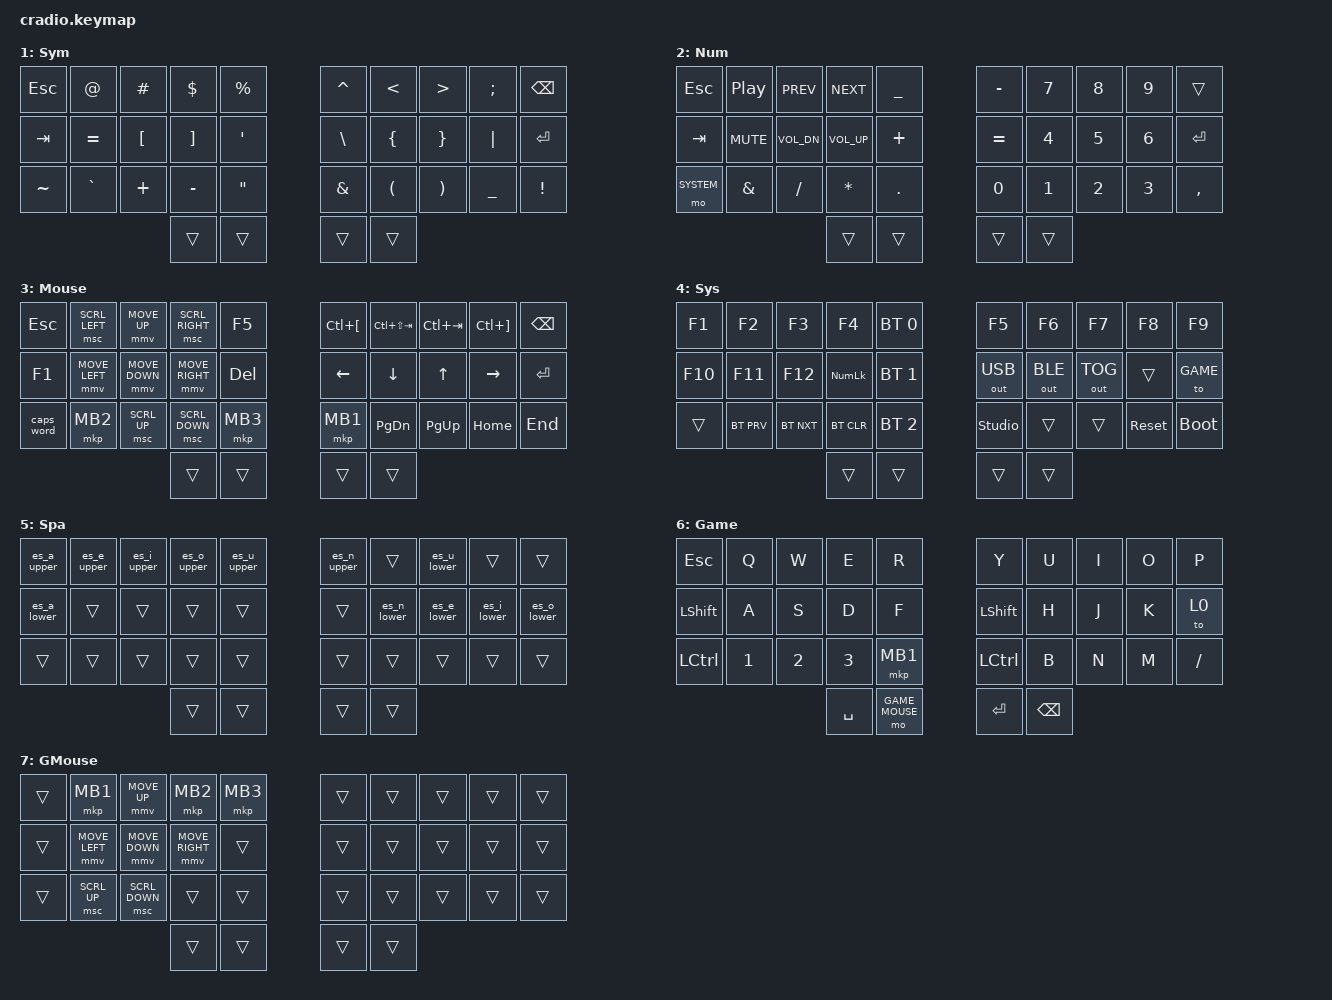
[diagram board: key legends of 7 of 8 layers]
// Copyright (c) 2022 The ZMK Contributors
// SPDX-License-Identifier: MIT

#include <behaviors.dtsi>
#include <dt-bindings/zmk/keys.h>
#include <dt-bindings/zmk/bt.h>
#include <dt-bindings/zmk/pointing.h>
#include <dt-bindings/zmk/outputs.h>
#include "spanish.dtsi"

// Layers adapted from benvallack/zmk-config at 84ae125986b18e1e6dfb1f2a6a15777429f29520.
// Keep numeric indices 1/2: the unchanged base thumb bindings refer to them.
#define SYMBOLS 1
#define NUMBERS 2
#define NAV 3
#define SYSTEM 4
#define SPANISH 5
#define GAME 6
#define GAME_MOUSE 7

// Home row mods macro
#define HRML(k1,k2,k3,k4) &ht LSHFT k1  &ht LALT k2  &ht LCTRL k3  &ht LGUI k4
#define HRMR(k1,k2,k3,k4) &ht RGUI k1  &ht RCTRL k2  &ht RALT k3  &ht RSHFT k4
#define MEDIA(k1,k2,k3,k4,k5) &kp k1 &kp k2 &kp k3 &kp k4 &kp k5

&mmv {
    x-input-code = <INPUT_REL_X>;
    y-input-code = <INPUT_REL_Y>;
    time-to-max-speed-ms = <300>;
    acceleration-exponent = <2>;
};

&msc {
    x-input-code = <INPUT_REL_HWHEEL>;
    y-input-code = <INPUT_REL_WHEEL>;
    time-to-max-speed-ms = <300>;
    acceleration-exponent = <1>;
};

/ {
    behaviors {
        // Space on tap, Windows Spanish layer on hold.
        // Resolve as a hold when another key is pressed, including after a space.
        thumb_spanish: thumb_spanish {
            compatible = "zmk,behavior-hold-tap";
            #binding-cells = <2>;
            flavor = "hold-preferred";
            tapping-term-ms = <200>;
            quick-tap-ms = <0>;
            bindings = <&mo>, <&kp>;
        };

        ht: hold_tap {
            compatible = "zmk,behavior-hold-tap";
            #binding-cells = <2>;
            flavor = "tap-preferred";
            tapping-term-ms = <220>;
            quick-tap-ms = <150>;
            require-prior-idle-ms = <100>;
            bindings = <&kp>, <&kp>;
        };
    };

    conditional_layers {
        compatible = "zmk,conditional-layers";
        tri_layer {
            if-layers = <SYMBOLS NUMBERS>;
            then-layer = <NAV>;
        };
    };

    keymap {
        compatible = "zmk,keymap";
        default_layer {
            display-name = "Base";
            bindings = <
        //╭──────────┬──────────┬──────────┬──────────┬──────────╮   ╭──────────┬──────────┬──────────┬──────────┬──────────╮
        //│  Q       │  W       │  E       │  R       │  T       │   │  Y       │  U       │  I       │  O       │  P       │
            &kp Q      &kp W      &kp F      &kp P      &kp G          &kp J      &kp L      &kp U      &kp Y      &kp SEMI
        //├──────────┼──────────┼──────────┼──────────┼──────────┤   ├──────────┼──────────┼──────────┼──────────┼──────────┤
        //│  A       │  S       │  D       │  F       │  G       │   │  H       │  J       │  K       │  L       │ ' "      │
            HRML(A,        R,         S,         T)     &kp D          &kp H      HRMR(N,        E,         I,        O)
        //├──────────┼──────────┼──────────┼──────────┼──────────┤   ├──────────┼──────────┼──────────┼──────────┼──────────┤
        //│  Z       │  X       │  C       │  V       │  B       │   │  N       │  M       │ , <      │ . >      │ / ?      │
            &kp Z      &kp X      &kp C      &kp V      &kp B          &kp K      &kp M      &kp COMMA  &kp DOT    &kp FSLH
        //╰──────────┴──────────┴──────────┼──────────┼──────────┤   ├──────────┼──────────┼──────────┴──────────┴──────────╯
                                            &lt 2 TAB   &kp ENTER     &thumb_spanish SPANISH SPACE  &lt 1 BSPC
        //                                 ╰──────────┴──────────╯   ╰──────────┴──────────╯
            >;
        };


        // Hold the base Backspace thumb. Also hold Tab for NAV.
        symbols_layer {
            display-name = "Sym";
            bindings = <
                &kp ESC    &kp AT     &kp HASH   &kp DLLR   &kp PRCNT    &kp CARET &kp LT    &kp GT    &kp SEMI  &kp BSPC
                &kp TAB    &kp EQUAL  &kp LBKT   &kp RBKT   &kp SQT      &kp BSLH  &kp LBRC  &kp RBRC  &kp PIPE  &kp ENTER
                &kp TILDE  &kp GRAVE  &kp PLUS   &kp MINUS  &kp DQT      &kp AMPS  &kp LPAR  &kp RPAR  &kp UNDER &kp EXCL
                                               &trans     &trans        &trans    &trans
            >;
        };

        // Hold the base Tab thumb. Right-hand numpad, left-hand media/math.
        numbers_layer {
            display-name = "Num";
            bindings = <
                &kp ESC    &kp C_PP   &kp C_PREV   &kp C_NEXT   &kp UNDER    &kp MINUS &kp N7 &kp N8 &kp N9 &trans
                &kp TAB    &kp C_MUTE &kp C_VOL_DN &kp C_VOL_UP &kp PLUS     &kp EQUAL &kp N4 &kp N5 &kp N6 &kp ENTER
                &mo SYSTEM &kp AMPS   &kp FSLH     &kp ASTRK    &kp DOT      &kp N0    &kp N1 &kp N2 &kp N3 &kp COMMA
                                                  &trans      &trans       &trans    &trans
            >;
        };

        // Both base layer thumbs. NAV is managed exclusively by conditional_layers.
        // Keep layer thumbs transparent: their release must reach the base bindings.
        navigation_layer {
            display-name = "Mouse";
            bindings = <
                &kp ESC    &msc SCRL_LEFT &mmv MOVE_UP   &msc SCRL_RIGHT &kp F5    &kp LC(LBKT) &kp LC(LS(TAB)) &kp LC(TAB) &kp LC(RBKT) &kp BSPC
                &kp F1     &mmv MOVE_LEFT &mmv MOVE_DOWN &mmv MOVE_RIGHT &kp DEL   &kp LEFT     &kp DOWN       &kp UP      &kp RIGHT    &kp ENTER
                &caps_word &mkp MB2       &msc SCRL_UP   &msc SCRL_DOWN  &mkp MB3  &mkp MB1     &kp PG_DN      &kp PG_UP   &kp HOME     &kp END
                                                       &trans          &trans     &trans        &trans
            >;
        };

        // Hold Tab, then hold the bottom-left key (base Z position).
        system_layer {
            display-name = "Sys";
            bindings = <
                &kp F1      &kp F2     &kp F3     &kp F4     &bt BT_SEL 0    &kp F5  &kp F6  &kp F7  &kp F8  &kp F9
                &kp F10     &kp F11    &kp F12    &kp KP_NUMLOCK &bt BT_SEL 1    &out OUT_USB &out OUT_BLE &out OUT_TOG &trans &to GAME
                &trans      &bt BT_PRV &bt BT_NXT &bt BT_CLR &bt BT_SEL 2    &studio_unlock &trans &trans &sys_reset &bootloader
                                                 &trans     &trans          &trans  &trans
            >;
        };
        // Hold the Space thumb. Lowercase characters occupy their base positions.
        // Uppercase characters are on the top row; do not hold other modifiers.
        spanish_layer {
            display-name = "Spa";
            bindings = <
                &es_a_upper &es_e_upper &es_i_upper &es_o_upper &es_u_upper    &es_n_upper &trans &es_u_lower &trans &trans
                &es_a_lower &trans &trans &trans &trans &trans &es_n_lower &es_e_lower &es_i_lower &es_o_lower
                &trans &trans &trans &trans &trans &trans &trans &trans &trans &trans
                                              &trans &trans &trans &trans
            >;
        };

        // Direct keypresses for gaming. System and Game share the exit/entry position.
        game_layer {
            display-name = "Game";
            bindings = <
                &kp ESC   &kp Q    &kp W    &kp E    &kp R      &kp Y     &kp U &kp I &kp O &kp P
                &kp LSHFT &kp A    &kp S    &kp D    &kp F      &kp LSHFT &kp H &kp J &kp K &to 0
                &kp LCTRL &kp N1   &kp N2   &kp N3   &mkp MB1   &kp LCTRL &kp B &kp N &kp M &kp FSLH
                                           &kp SPACE &mo GAME_MOUSE     &kp ENTER &kp BSPC
            >;
        };

        // Hold the second left thumb for pointer control on the movement cluster.
        game_mouse_layer {
            display-name = "GMouse";
            bindings = <
                &trans &mkp MB1       &mmv MOVE_UP   &mkp MB2        &mkp MB3    &trans &trans &trans &trans &trans
                &trans &mmv MOVE_LEFT &mmv MOVE_DOWN &mmv MOVE_RIGHT &trans      &trans &trans &trans &trans &trans
                &trans &msc SCRL_UP   &msc SCRL_DOWN &trans          &trans      &trans &trans &trans &trans &trans
                                                     &trans          &trans      &trans &trans
            >;
        };
    };
};
